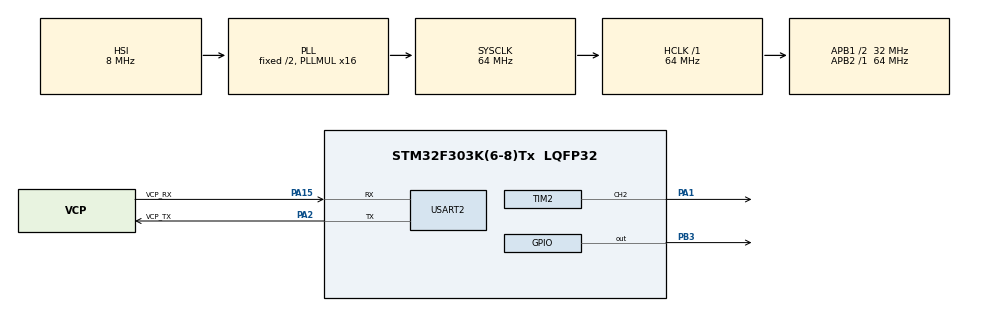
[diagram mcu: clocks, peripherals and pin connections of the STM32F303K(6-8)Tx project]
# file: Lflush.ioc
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Mcu.Family=STM32F3
RCC.CortexFreq_Value=64000000
PF0\ /\ OSC_IN.Mode=HSE-External-Clock-Source
PA14.GPIO_Label=SWCLK
RCC.SYSCLKSourceVirtual=RCC_SYSCLKSOURCE_PLLCLK
TIM2.Channel-PWM\ Generation2\ CH2=TIM_CHANNEL_2
RCC.APB1CLKDivider=RCC_HCLK_DIV2
ProjectManager.StackSize=0x400
PA13.Signal=SYS_JTMS-SWDIO
PA15.GPIO_Label=VCP_RX
SH.S_TIM2_CH2.0=TIM2_CH2,PWM Generation2 CH2
ProjectManager.TargetToolchain=STM32CubeIDE
RCC.HCLKFreq_Value=64000000
RCC.APB2TimFreq_Value=64000000
PA1.Signal=S_TIM2_CH2
RCC.AHBFreq_Value=64000000
RCC.HSE_VALUE=8000000
board=NUCLEO-F303K8
USART2.VirtualMode-Asynchronous=VM_ASYNC
PA15.Mode=Asynchronous
RCC.PLLMUL=RCC_PLL_MUL16
RCC.APB2Freq_Value=64000000
PF0\ /\ OSC_IN.Signal=RCC_OSC_IN
VP_TIM2_VS_ClockSourceINT.Mode=Internal
PA14.Mode=Serial_Wire
PF0\ /\ OSC_IN.GPIO_Label=MCO
TIM2.Period=39
PA13.Mode=Serial_Wire
Mcu.Name=STM32F303K(6-8)Tx
PA13.GPIO_Label=SWDIO
PA2.Signal=USART2_TX
PB3.Signal=GPIO_Output
RCC.SYSCLKFreq_VALUE=64000000
Mcu.Package=LQFP32
TIM2.Prescaler=63
PA2.GPIO_Label=VCP_TX
PA14.Signal=SYS_JTCK-SWCLK
PA15.Signal=USART2_RX
ProjectManager.HeapSize=0x200
RCC.HSI_VALUE=8000000
NVIC.PriorityGroup=NVIC_PRIORITYGROUP_4
RCC.APB1TimFreq_Value=64000000
PA2.Mode=Asynchronous
TIM2.AutoReloadPreload=TIM_AUTORELOAD_PRELOAD_ENABLE
RCC.APB1Freq_Value=32000000

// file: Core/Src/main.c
/* USER CODE BEGIN Header */
/**
  ******************************************************************************
  * @file           : main.c
  * @brief          : Main program body
  ******************************************************************************
  * @attention
  *
  * <h2><center>&copy; Copyright (c) 2021 STMicroelectronics.
  * All rights reserved.</center></h2>
  *
  * This software component is licensed by ST under BSD 3-Clause license,
  * the "License"; You may not use this file except in compliance with the
  * License. You may obtain a copy of the License at:
  *                        opensource.org/licenses/BSD-3-Clause
  *
  ******************************************************************************
  */
/* USER CODE END Header */
#include "main.h"

TIM_HandleTypeDef htim2;

UART_HandleTypeDef huart2;

void SystemClock_Config(void);
static void MX_GPIO_Init(void);
static void MX_USART2_UART_Init(void);
static void MX_TIM2_Init(void);

int main(void)
{

  /* MCU Configuration--------------------------------------------------------*/

  /* Reset of all peripherals, Initializes the Flash interface and the Systick. */

	HAL_Init();

  /* Configure the system clock */
  SystemClock_Config();

  /* Initialize all configured peripherals */
  MX_GPIO_Init();
  MX_USART2_UART_Init();
  MX_TIM2_Init();

  /* Infinite loop */
  /* USER CODE BEGIN WHILE */
  HAL_TIM_PWM_Start(&htim2,TIM_CHANNEL_2);
  __HAL_TIM_SET_COMPARE(&htim2,TIM_CHANNEL_2,35);
  while (1)
  {
	  HAL_GPIO_WritePin(GPIOB, GPIO_PIN_3,SET);
	  HAL_Delay(3000);
	  HAL_GPIO_WritePin(GPIOB, GPIO_PIN_3,RESET);
	  HAL_Delay(3000);
	 /*/
	  if(HAL_GPIO_ReadPin(GPIOB,GPIO_PIN_4)==0)
	  {
	  */

	 	 HAL_Delay(10);
	 	 /*/
	  }
	  else
	  {
		  __HAL_TIM_SET_COMPARE(&htim2,TIM_CHANNEL_2,0);
	  }
	  /*/
	  /*/
	  if(HAL_GPIO_ReadPin(GPIOB,GPIO_PIN_4)==0)
	  	  {
		  HAL_GPIO_WritePin(GPIOB, GPIO_PIN_3,SET);
	  	  }
	  else{
		  HAL_GPIO_WritePin(GPIOB, GPIO_PIN_3,RESET);
	  	  }
	  */

    /* USER CODE END WHILE */

  }
}

void SystemClock_Config(void)
{
  RCC_OscInitTypeDef RCC_OscInitStruct = {0};
  RCC_ClkInitTypeDef RCC_ClkInitStruct = {0};

  /** Initializes the RCC Oscillators according to the specified parameters
  * in the RCC_OscInitTypeDef structure.
  */
  RCC_OscInitStruct.OscillatorType = RCC_OSCILLATORTYPE_HSI;
  RCC_OscInitStruct.HSIState = RCC_HSI_ON;
  RCC_OscInitStruct.HSICalibrationValue = RCC_HSICALIBRATION_DEFAULT;
  RCC_OscInitStruct.PLL.PLLState = RCC_PLL_ON;
  RCC_OscInitStruct.PLL.PLLSource = RCC_PLLSOURCE_HSI;
  RCC_OscInitStruct.PLL.PLLMUL = RCC_PLL_MUL16;
  if (HAL_RCC_OscConfig(&RCC_OscInitStruct) != HAL_OK)
  {
    Error_Handler();
  }
  /** Initializes the CPU, AHB and APB buses clocks
  */
  RCC_ClkInitStruct.ClockType = RCC_CLOCKTYPE_HCLK|RCC_CLOCKTYPE_SYSCLK
                              |RCC_CLOCKTYPE_PCLK1|RCC_CLOCKTYPE_PCLK2;
  RCC_ClkInitStruct.SYSCLKSource = RCC_SYSCLKSOURCE_PLLCLK;
  RCC_ClkInitStruct.AHBCLKDivider = RCC_SYSCLK_DIV1;
  RCC_ClkInitStruct.APB1CLKDivider = RCC_HCLK_DIV2;
  RCC_ClkInitStruct.APB2CLKDivider = RCC_HCLK_DIV1;

  if (HAL_RCC_ClockConfig(&RCC_ClkInitStruct, FLASH_LATENCY_2) != HAL_OK)
  {
    Error_Handler();
  }
}

static void MX_TIM2_Init(void)
{

  TIM_ClockConfigTypeDef sClockSourceConfig = {0};
  TIM_MasterConfigTypeDef sMasterConfig = {0};
  TIM_OC_InitTypeDef sConfigOC = {0};

  htim2.Instance = TIM2;
  htim2.Init.Prescaler = 63;
  htim2.Init.CounterMode = TIM_COUNTERMODE_UP;
  htim2.Init.Period = 39;
  htim2.Init.ClockDivision = TIM_CLOCKDIVISION_DIV1;
  htim2.Init.AutoReloadPreload = TIM_AUTORELOAD_PRELOAD_ENABLE;
  if (HAL_TIM_Base_Init(&htim2) != HAL_OK)
  {
    Error_Handler();
  }
  sClockSourceConfig.ClockSource = TIM_CLOCKSOURCE_INTERNAL;
  if (HAL_TIM_ConfigClockSource(&htim2, &sClockSourceConfig) != HAL_OK)
  {
    Error_Handler();
  }
  if (HAL_TIM_PWM_Init(&htim2) != HAL_OK)
  {
    Error_Handler();
  }
  sMasterConfig.MasterOutputTrigger = TIM_TRGO_RESET;
  sMasterConfig.MasterSlaveMode = TIM_MASTERSLAVEMODE_DISABLE;
  if (HAL_TIMEx_MasterConfigSynchronization(&htim2, &sMasterConfig) != HAL_OK)
  {
    Error_Handler();
  }
  sConfigOC.OCMode = TIM_OCMODE_PWM1;
  sConfigOC.Pulse = 0;
  sConfigOC.OCPolarity = TIM_OCPOLARITY_HIGH;
  sConfigOC.OCFastMode = TIM_OCFAST_DISABLE;
  if (HAL_TIM_PWM_ConfigChannel(&htim2, &sConfigOC, TIM_CHANNEL_2) != HAL_OK)
  {
    Error_Handler();
  }
  HAL_TIM_MspPostInit(&htim2);

}

static void MX_USART2_UART_Init(void)
{

  huart2.Instance = USART2;
  huart2.Init.BaudRate = 38400;
  huart2.Init.WordLength = UART_WORDLENGTH_8B;
  huart2.Init.StopBits = UART_STOPBITS_1;
  huart2.Init.Parity = UART_PARITY_NONE;
  huart2.Init.Mode = UART_MODE_TX_RX;
  huart2.Init.HwFlowCtl = UART_HWCONTROL_NONE;
  huart2.Init.OverSampling = UART_OVERSAMPLING_16;
  huart2.Init.OneBitSampling = UART_ONE_BIT_SAMPLE_DISABLE;
  huart2.AdvancedInit.AdvFeatureInit = UART_ADVFEATURE_NO_INIT;
  if (HAL_UART_Init(&huart2) != HAL_OK)
  {
    Error_Handler();
  }

}

static void MX_GPIO_Init(void)
{
  GPIO_InitTypeDef GPIO_InitStruct = {0};

  /* GPIO Ports Clock Enable */
  __HAL_RCC_GPIOF_CLK_ENABLE();
  __HAL_RCC_GPIOA_CLK_ENABLE();
  __HAL_RCC_GPIOB_CLK_ENABLE();

  /*Configure GPIO pin Output Level */
  HAL_GPIO_WritePin(GPIOB, GPIO_PIN_3, GPIO_PIN_RESET);

  /*Configure GPIO pin : PB3 */
  GPIO_InitStruct.Pin = GPIO_PIN_3;
  GPIO_InitStruct.Mode = GPIO_MODE_OUTPUT_PP;
  GPIO_InitStruct.Pull = GPIO_NOPULL;
  GPIO_InitStruct.Speed = GPIO_SPEED_FREQ_LOW;
  HAL_GPIO_Init(GPIOB, &GPIO_InitStruct);

}

void Error_Handler(void)
{
  __disable_irq();
  while (1)
  {
  }
}

/************************ (C) COPYRIGHT STMicroelectronics *****END OF FILE****/
